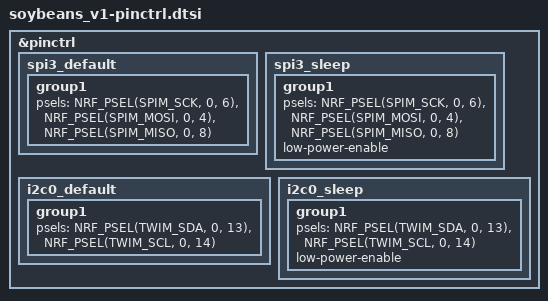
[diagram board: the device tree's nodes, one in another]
/*
 * Copyright (c) 2022 The ZMK Contributors
 * SPDX-License-Identifier: MIT
 */

&pinctrl {
    spi3_default: spi3_default {
        group1 {
            psels = <NRF_PSEL(SPIM_SCK, 0, 6)>,
                    <NRF_PSEL(SPIM_MOSI, 0, 4)>,
                    <NRF_PSEL(SPIM_MISO, 0, 8)>;
        };
    };
    spi3_sleep: spi3_sleep {
        group1 {
            psels = <NRF_PSEL(SPIM_SCK, 0, 6)>,
                    <NRF_PSEL(SPIM_MOSI, 0, 4)>,
                    <NRF_PSEL(SPIM_MISO, 0, 8)>;
            low-power-enable;
        };
    };

    i2c0_default: i2c0_default {
        group1 {
            psels = <NRF_PSEL(TWIM_SDA, 0, 13)>,
                    <NRF_PSEL(TWIM_SCL, 0, 14)>;
        };
    };

    i2c0_sleep: i2c0_sleep {
        group1 {
            psels = <NRF_PSEL(TWIM_SDA, 0, 13)>,
                    <NRF_PSEL(TWIM_SCL, 0, 14)>;
            low-power-enable;
        };
    };
};
